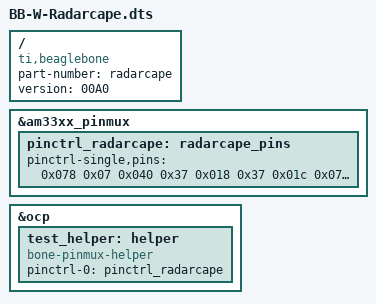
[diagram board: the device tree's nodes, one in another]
/*
 * Copyright (C) 2012 Texas Instruments Incorporated - http://www.ti.com/
 *
 * This program is free software; you can redistribute it and/or modify
 * it under the terms of the GNU General Public License version 2 as
 * published by the Free Software Foundation.
 *
 * Adapted to fit the Radarcape based on the beaglebone white board.
 * Pin definitions were taken from the original Radarcape, by Guenter Koellner.
 */
/dts-v1/;
/plugin/;

/ {
    compatible = "ti,beaglebone";

    /* identification */
    part-number = "radarcape";
    version = "00A0";

    fragment@0 {
        target = <&am33xx_pinmux>;
        __overlay__ {
            pinctrl_radarcape: radarcape_pins {
                pinctrl-single,pins = <
                    /* Watchdog retrigger output */
                    0x078 0x07  /* P9_12 GPIO1_30 #60 Output Mode7 */            
 
                    /* GPS 1PPS Input */
                    0x040 0x37  /* P9_15 GPIO1_16 #48 Input  Mode7 pullup    PPS1 input */
                    
                    /* FPGA Pins */ 
                    0x018 0x37  /* P8_3  GPIO1_6  #38 Input  Mode7 pullup    CONF_DONE  */
                    0x01c 0x07  /* P8_4  GPIO1_7  #39 Output Mode7           DCLK       */
                    0x008 0x37  /* P8_5  GPIO1_2  #34 Input  Mode7 pullup    nStatus    */
                    0x030 0x07  /* P8_12 GPIO1_12 #44 Output Mode7           DATA0      */
                    0x014 0x07  /* P8_22 GPIO1_5  #37 Output Mode7           nCONF      */

                    /* UART5 CTS/RTS as addon to the default UART5 device tree settings */ 
                    0x0d8 0x36  /* P8_31 UART5_CTSN   Input  Mode6 pullup    CTS input  */
                    0x0dc 0x06  /* P8_32 UART5_RTSN   Output Mode6 no pull   RTS output */
                >;
            };
        };
    };

    fragment@1 {
        target = <&ocp>;
        __overlay__ {
            test_helper: helper {
                compatible = "bone-pinmux-helper";
                pinctrl-names = "default";
                pinctrl-0 = <&pinctrl_radarcape>;
                status = "okay";
            };
        };
    };
};
